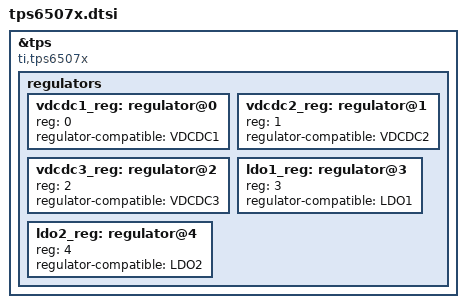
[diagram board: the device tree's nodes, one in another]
// SPDX-License-Identifier: GPL-2.0-only
/*
 * Copyright (C) 2013 Texas Instruments Incorporated - http://www.ti.com/
 */

/*
 * Integrated Power Management Chip
 * http://www.ti.com/lit/ds/symlink/tps65070.pdf
 */

&tps {
	compatible = "ti,tps6507x";

	regulators {
		#address-cells = <1>;
		#size-cells = <0>;

		vdcdc1_reg: regulator@0 {
			reg = <0>;
			regulator-compatible = "VDCDC1";
		};

		vdcdc2_reg: regulator@1 {
			reg = <1>;
			regulator-compatible = "VDCDC2";
		};

		vdcdc3_reg: regulator@2 {
			reg = <2>;
			regulator-compatible = "VDCDC3";
		};

		ldo1_reg: regulator@3 {
			reg = <3>;
			regulator-compatible = "LDO1";
		};

		ldo2_reg: regulator@4 {
			reg = <4>;
			regulator-compatible = "LDO2";
		};

	};
};
